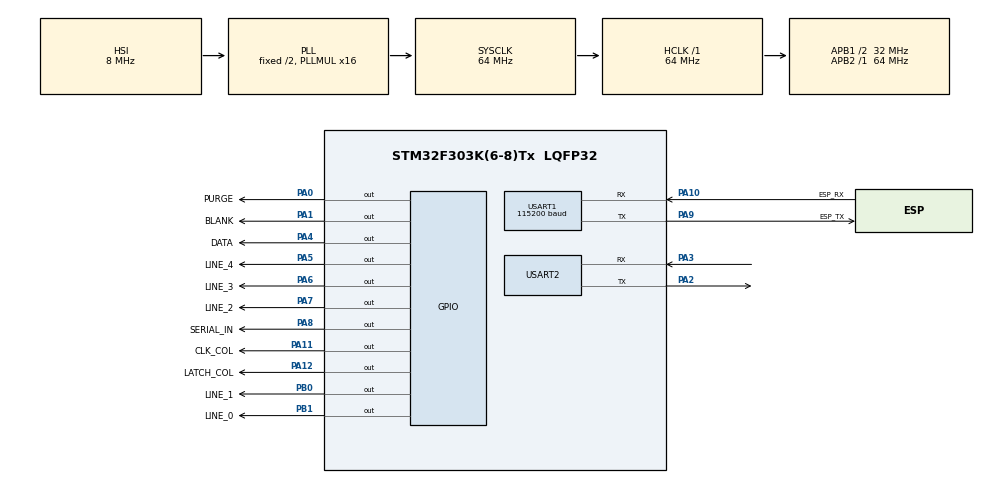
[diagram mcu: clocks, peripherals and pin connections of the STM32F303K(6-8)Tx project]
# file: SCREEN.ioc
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Dma.Request0=USART1_RX
Dma.USART1_RX.0.Direction=DMA_PERIPH_TO_MEMORY
Dma.USART1_RX.0.Instance=DMA1_Channel5
Dma.USART1_RX.0.MemDataAlignment=DMA_MDATAALIGN_BYTE
Dma.USART1_RX.0.MemInc=DMA_MINC_ENABLE
Dma.USART1_RX.0.Mode=DMA_CIRCULAR
Dma.USART1_RX.0.PeriphDataAlignment=DMA_PDATAALIGN_BYTE
Dma.USART1_RX.0.PeriphInc=DMA_PINC_DISABLE
Dma.USART1_RX.0.Priority=DMA_PRIORITY_HIGH
Mcu.Family=STM32F3
Mcu.Name=STM32F303K(6-8)Tx
Mcu.Package=LQFP32
NVIC.DMA1_Channel5_IRQn=true\:0\:0\:false\:false\:true\:false
NVIC.PriorityGroup=NVIC_PRIORITYGROUP_4
NVIC.TIM2_IRQn=true\:0\:0\:false\:false\:true\:true
NVIC.USART1_IRQn=true\:0\:0\:false\:false\:true\:true
PA0.GPIO_Label=PURGE
PA0.GPIO_Speed=GPIO_SPEED_FREQ_HIGH
PA0.Signal=GPIO_Output
PA1.GPIO_Label=BLANK
PA1.GPIO_Speed=GPIO_SPEED_FREQ_HIGH
PA1.Signal=GPIO_Output
PA10.GPIO_Label=ESP_RX
PA10.Mode=Asynchronous
PA10.Signal=USART1_RX
PA11.GPIO_Label=CLK_COL
PA11.GPIO_Speed=GPIO_SPEED_FREQ_HIGH
PA11.Signal=GPIO_Output
PA12.GPIO_Label=LATCH_COL
PA12.GPIO_Speed=GPIO_SPEED_FREQ_HIGH
PA12.Signal=GPIO_Output
PA13.Mode=Serial_Wire
PA13.Signal=SYS_JTMS-SWDIO
PA14.Mode=Serial_Wire
PA14.Signal=SYS_JTCK-SWCLK
PA2.Mode=Asynchronous
PA2.Signal=USART2_TX
PA3.Mode=Asynchronous
PA3.Signal=USART2_RX
PA4.GPIO_Label=DATA
PA4.GPIO_Speed=GPIO_SPEED_FREQ_HIGH
PA4.Signal=GPIO_Output
PA5.GPIO_Label=LINE_4
PA5.GPIO_Speed=GPIO_SPEED_FREQ_HIGH
PA5.Signal=GPIO_Output
PA6.GPIO_Label=LINE_3
PA6.GPIO_Speed=GPIO_SPEED_FREQ_HIGH
PA6.Signal=GPIO_Output
PA7.GPIO_Label=LINE_2
PA7.GPIO_Speed=GPIO_SPEED_FREQ_HIGH
PA7.Signal=GPIO_Output
PA8.GPIO_Label=SERIAL_IN
PA8.GPIO_Speed=GPIO_SPEED_FREQ_HIGH
PA8.Signal=GPIO_Output
PA9.GPIO_Label=ESP_TX
PA9.Mode=Asynchronous
PA9.Signal=USART1_TX
PB0.GPIO_Label=LINE_1
PB0.GPIO_Speed=GPIO_SPEED_FREQ_HIGH
PB0.Signal=GPIO_Output
PB1.GPIO_Label=LINE_0
PB1.GPIO_Speed=GPIO_SPEED_FREQ_HIGH
PB1.Signal=GPIO_Output
ProjectManager.HeapSize=0x200
ProjectManager.StackSize=0x400
ProjectManager.TargetToolchain=Makefile
RCC.AHBFreq_Value=64000000
RCC.APB1CLKDivider=RCC_HCLK_DIV2
RCC.APB1Freq_Value=32000000
RCC.APB1TimFreq_Value=64000000
RCC.APB2Freq_Value=64000000
RCC.APB2TimFreq_Value=64000000
RCC.CortexFreq_Value=64000000
RCC.HCLKFreq_Value=64000000
RCC.HSE_VALUE=8000000
RCC.HSI_VALUE=8000000
RCC.PLLMUL=RCC_PLL_MUL16
RCC.SYSCLKFreq_VALUE=64000000
RCC.SYSCLKSourceVirtual=RCC_SYSCLKSOURCE_PLLCLK
TIM2.Period=57143-1
TIM2.Prescaler=0
USART1.BaudRate=115200
USART1.VirtualMode-Asynchronous=VM_ASYNC
USART1.WordLength=WORDLENGTH_8B
USART2.VirtualMode-Asynchronous=VM_ASYNC
VP_TIM2_VS_ClockSourceINT.Mode=Internal
board=SCREEN

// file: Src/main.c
/**
  ******************************************************************************
  * @file           : main.c
  * @brief          : Main program body
  ******************************************************************************
  ** This notice applies to any and all portions of this file
  * that are not between comment pairs USER CODE BEGIN and
  * USER CODE END. Other portions of this file, whether
  * inserted by the user or by software development tools
  * are owned by their respective copyright owners.
  *
  * COPYRIGHT(c) 2018 STMicroelectronics
  *
  * Redistribution and use in source and binary forms, with or without modification,
  * are permitted provided that the following conditions are met:
  *   1. Redistributions of source code must retain the above copyright notice,
  *      this list of conditions and the following disclaimer.
  *   2. Redistributions in binary form must reproduce the above copyright notice,
  *      this list of conditions and the following disclaimer in the documentation
  *      and/or other materials provided with the distribution.
  *   3. Neither the name of STMicroelectronics nor the names of its contributors
  *      may be used to endorse or promote products derived from this software
  *      without specific prior written permission.
  *
  * THIS SOFTWARE IS PROVIDED BY THE COPYRIGHT HOLDERS AND CONTRIBUTORS "AS IS"
  * AND ANY EXPRESS OR IMPLIED WARRANTIES, INCLUDING, BUT NOT LIMITED TO, THE
  * IMPLIED WARRANTIES OF MERCHANTABILITY AND FITNESS FOR A PARTICULAR PURPOSE ARE
  * DISCLAIMED. IN NO EVENT SHALL THE COPYRIGHT HOLDER OR CONTRIBUTORS BE LIABLE
  * FOR ANY DIRECT, INDIRECT, INCIDENTAL, SPECIAL, EXEMPLARY, OR CONSEQUENTIAL
  * DAMAGES (INCLUDING, BUT NOT LIMITED TO, PROCUREMENT OF SUBSTITUTE GOODS OR
  * SERVICES; LOSS OF USE, DATA, OR PROFITS; OR BUSINESS INTERRUPTION) HOWEVER
  * CAUSED AND ON ANY THEORY OF LIABILITY, WHETHER IN CONTRACT, STRICT LIABILITY,
  * OR TORT (INCLUDING NEGLIGENCE OR OTHERWISE) ARISING IN ANY WAY OUT OF THE USE
  * OF THIS SOFTWARE, EVEN IF ADVISED OF THE POSSIBILITY OF SUCH DAMAGE.
  *
  ******************************************************************************
  */
#include "main.h"
#include "stm32f3xx_hal.h"
#include "dma.h"
#include "tim.h"
#include "usart.h"
#include "gpio.h"

/* USER CODE BEGIN Includes */
#include <stdbool.h>
#include "robotronik_protocol.h"
#include "robotronik_protocol_stm32.h"
#include "display.h"
/* USER CODE END Includes */

/* USER CODE BEGIN PV */
/* Private variables ---------------------------------------------------------*/

/* USER CODE END PV */

void SystemClock_Config(void);

/* USER CODE BEGIN PFP */
/* Private function prototypes -----------------------------------------------*/

/* USER CODE END PFP */

/* USER CODE BEGIN 0 */

/**
 * Interruption timer -> tim.c
 * Robotronik Protocol -> usart.h, usart.c
 * Interruptions UART -> stm32f3xx_it.c
 */

volatile uint16_t score = 123;
volatile int refresh = 0;
/*
 * Variable indiquant s'il faut rafraîchir l'écran ou non. Elle est
 * mise à jour dans le traitant d'interruption du timer.
 */

/* USER CODE END 0 */

int main(void)
{

  /* MCU Configuration----------------------------------------------------------*/

  /* Reset of all peripherals, Initializes the Flash interface and the Systick. */
  HAL_Init();

  /* Configure the system clock */
  SystemClock_Config();

  /* Initialize all configured peripherals */
  MX_GPIO_Init();
  MX_DMA_Init();
  MX_USART1_UART_Init();
  MX_TIM2_Init();
  MX_USART2_UART_Init();
  /* USER CODE BEGIN 2 */

  //Initialisation UART
  RP_Init_Interface(&esp_interface, RP_UART_Transmit, RP_Get_Tick);

  RP_INIT_UART_DMA(DMA1, LL_DMA_CHANNEL_5, USART1, esp_interface);

  //Lancement du timer de rafraîchissement
  HAL_TIM_Base_Start_IT(&htim2);

  /* USER CODE END 2 */

  /* Infinite loop */
  /* USER CODE BEGIN WHILE */

  blank_screen();

  while (1)
  {
    //Affichage
    display_score(score);

  /* USER CODE END WHILE */

  }

}

void SystemClock_Config(void)
{

  RCC_OscInitTypeDef RCC_OscInitStruct;
  RCC_ClkInitTypeDef RCC_ClkInitStruct;
  RCC_PeriphCLKInitTypeDef PeriphClkInit;

    /**Initializes the CPU, AHB and APB busses clocks
    */
  RCC_OscInitStruct.OscillatorType = RCC_OSCILLATORTYPE_HSI;
  RCC_OscInitStruct.HSIState = RCC_HSI_ON;
  RCC_OscInitStruct.HSICalibrationValue = 16;
  RCC_OscInitStruct.PLL.PLLState = RCC_PLL_ON;
  RCC_OscInitStruct.PLL.PLLSource = RCC_PLLSOURCE_HSI;
  RCC_OscInitStruct.PLL.PLLMUL = RCC_PLL_MUL16;
  if (HAL_RCC_OscConfig(&RCC_OscInitStruct) != HAL_OK)
  {
    _Error_Handler(__FILE__, __LINE__);
  }

    /**Initializes the CPU, AHB and APB busses clocks
    */
  RCC_ClkInitStruct.ClockType = RCC_CLOCKTYPE_HCLK|RCC_CLOCKTYPE_SYSCLK
                              |RCC_CLOCKTYPE_PCLK1|RCC_CLOCKTYPE_PCLK2;
  RCC_ClkInitStruct.SYSCLKSource = RCC_SYSCLKSOURCE_PLLCLK;
  RCC_ClkInitStruct.AHBCLKDivider = RCC_SYSCLK_DIV1;
  RCC_ClkInitStruct.APB1CLKDivider = RCC_HCLK_DIV2;
  RCC_ClkInitStruct.APB2CLKDivider = RCC_HCLK_DIV1;

  if (HAL_RCC_ClockConfig(&RCC_ClkInitStruct, FLASH_LATENCY_2) != HAL_OK)
  {
    _Error_Handler(__FILE__, __LINE__);
  }

  PeriphClkInit.PeriphClockSelection = RCC_PERIPHCLK_USART1;
  PeriphClkInit.Usart1ClockSelection = RCC_USART1CLKSOURCE_PCLK1;
  if (HAL_RCCEx_PeriphCLKConfig(&PeriphClkInit) != HAL_OK)
  {
    _Error_Handler(__FILE__, __LINE__);
  }

    /**Configure the Systick interrupt time
    */
  HAL_SYSTICK_Config(HAL_RCC_GetHCLKFreq()/1000);

    /**Configure the Systick
    */
  HAL_SYSTICK_CLKSourceConfig(SYSTICK_CLKSOURCE_HCLK);

  /* SysTick_IRQn interrupt configuration */
  HAL_NVIC_SetPriority(SysTick_IRQn, 0, 0);
}

void _Error_Handler(char *file, int line)
{
  while(1)
  {
  }
}

/************************ (C) COPYRIGHT STMicroelectronics *****END OF FILE****/
